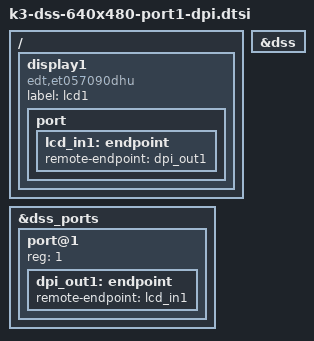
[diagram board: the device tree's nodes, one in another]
// SPDX-License-Identifier: GPL-2.0
/*
 * Device Tree Source for K3 SoC Family
 *
 * Copyright (C) 2016-2018 Texas Instruments Incorporated - http://www.ti.com/
 */


/ {
	display1 {
		/* Just a 640x480 panel with support in panel-simple driver. */
		compatible = "edt,et057090dhu";

		label = "lcd1";
		status = "ok";

		port {
			lcd_in1: endpoint {
				remote-endpoint = <&dpi_out1>;
			};
		};
	};
};

&dss {
	status = "ok";
};

&dss_ports {
	   port@1 {
		reg = <1>;

		dpi_out1: endpoint {
			remote-endpoint = <&lcd_in1>;
		};
	};
};
